VERSION ""

NS_ :

BS_:

BU_: DBG MASTER MOTOR SENSORS GEO BT

BO_ 95 HB_SENSORS: 1 SENSORS
 SG_ SENSOR_ALIVE : 0|1@1+ (1,0) [0|0] "HB-S" MASTER,MOTOR,GEO,BT

BO_ 96 HB_MOTORS: 1 MOTOR
 SG_ MOTOR_ALIVE : 0|1@1+ (1,0) [0|0] "HB-M" MASTER,SENSORS,GEO,BT

BO_ 97 HB_GEO: 1 GEO
 SG_ GEO_ALIVE : 0|1@1+ (1,0) [0|0] "HB-G" MASTER,SENSORS,MOTOR,BT

BO_ 98 HB_BT: 1 BT
 SG_ BT_ALIVE : 0|1@1+ (1,0) [0|0] "HB-BT" MASTER,SENSORS,MOTOR,GEO

BO_ 99 HB_MASTER: 1 MASTER
 SG_ MASTER_ALIVE : 0|1@1+ (1,0) [0|0] "HB-MT" BT,SENSORS,MOTOR,GEO

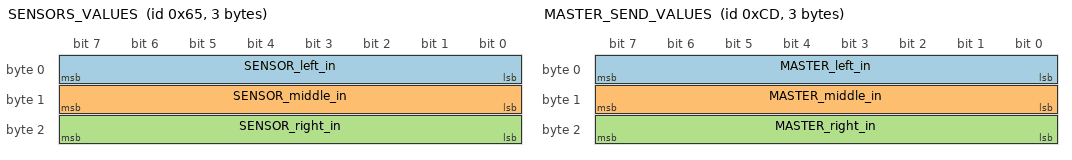
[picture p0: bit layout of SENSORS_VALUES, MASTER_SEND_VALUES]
BO_ 101 SENSORS_VALUES: 3 SENSORS
 SG_ SENSOR_left_in : 0|8@1+ (1,0) [0|0] "Inches" MASTER
 SG_ SENSOR_middle_in : 8|8@1+ (1,0) [0|0] "Inches" MASTER
 SG_ SENSOR_right_in : 16|8@1+ (1,0) [0|0] "Inches" MASTER

BO_ 200 MASTER_INITIALIZE: 1 MASTER
 SG_ MASTER_Init_Boards : 0|8@1+ (1,0) [0|0] "" SENSORS, MOTOR, BT, GEO

BO_ 203 MASTER_SPEED: 2 MASTER
 SG_ MASTER_Maintain_Speed : 0|8@1+ (1,0) [0|30] "mph" MOTOR
 SG_ MASTER_Maintain_Direction : 8|8@1+ (1,0) [0|12] "" MOTOR

BO_ 205 MASTER_SEND_VALUES: 3 MASTER
 SG_ MASTER_left_in : 0|8@1+ (1,0) [0|0] "Inches" SENSORS
 SG_ MASTER_middle_in : 8|8@1+ (1,0) [0|0] "Inches" SENSORS
 SG_ MASTER_right_in : 16|8@1+ (1,0) [0|0] "Inches" SENSORS

BO_ 301 MOTOR_STATUS: 3 MOTOR
 SG_ MOTOR_Send_Speed : 0|8@1+ (0.1,0) [0|0] "mph" MASTER
 SG_ MOTOR_Send_PWM : 8|12@1+ (0.01,0) [0|0] "PWM" MASTER
